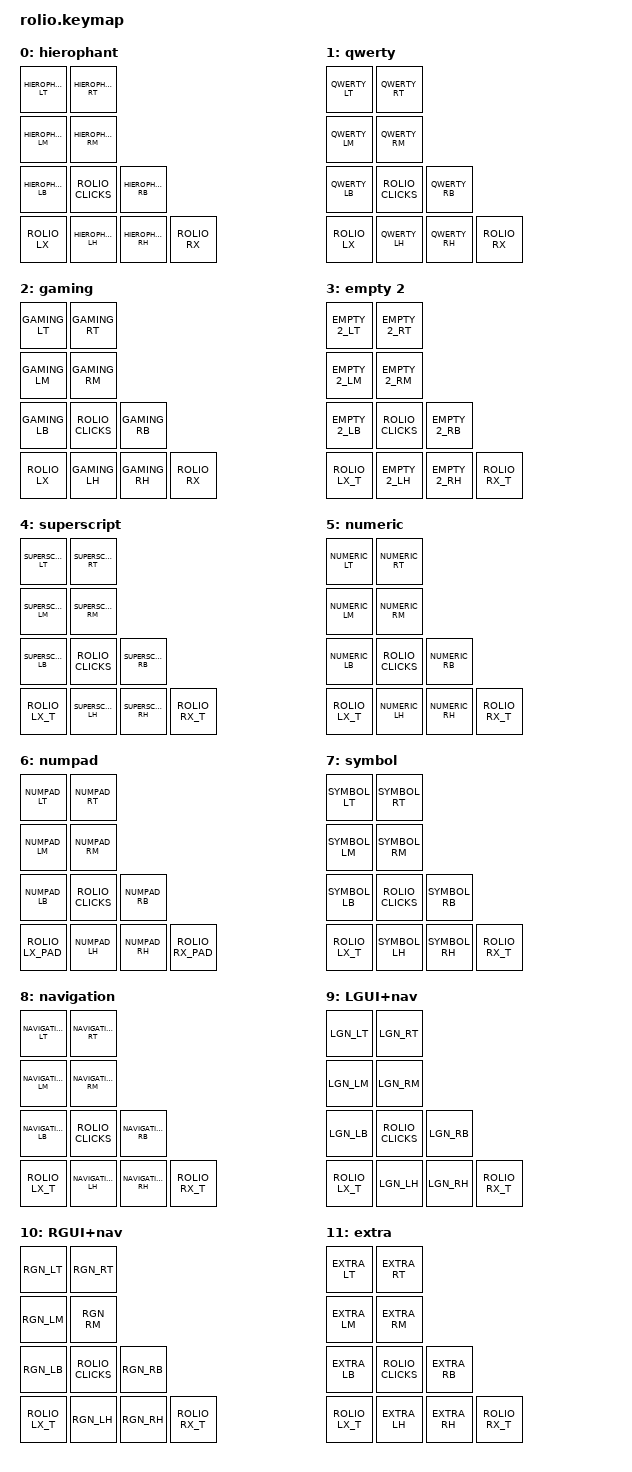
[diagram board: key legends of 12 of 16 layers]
// -*- mode: dts -*-
/*
 * Rolio ("Rolio Three") running the shared jjb layout.
 *
 * 48 matrix positions, 46 keycaps. Six columns per half exactly like the corne,
 * so X_LT / X_LM / X_LB drop straight in. What the shared layout has no slot
 * for is the bottom row's two outer "sometimes" keys per side (Sofle-style)
 * and the roller's push switch -- bound below rather than in jjb.keymap, since
 * no other board in this config has them.
 *
 * Hardware: Rolio Core V3 (config/boards/rolio/rolio3), vista508 display and
 * roller on the left half, Cirque trackpad and a second roller on the right.
 * Matrix wiring verified against the board, not taken from the vendor tree --
 * see config/boards/shields/rolio/rolio.dtsi.
 */

#define CONFIG_WIRELESS

#include "rolio48.h"
#include "jjb.keymap"

/* Bottom-row extras, left pair is (outer, inner), right pair is (inner, outer).
   The shared layout has no slot for these, so they are bound here.

   On the base layers the left pair splits apart the tap-dance that the outer
   left thumb (&sl_sym_or_numpad) otherwise packs onto one key: tap for sticky
   SYMBOL, double-tap for smart NUMPAD. Given dedicated keys, both are a single
   press. Swap the two if the inner position suits SYMBOL better in practice.

   The right pair stays inert -- mirroring these would collide with the right
   half's own thumb behaviours. */
#define ROLIO_LX &sl_long SYMBOL  &numpad_word NUMPAD
/* Mirrors the left pair. Note the order differs: the left pair reads
   outer-then-inner, the right inner-then-outer, so both put numpad on the
   fourth thumb key and sticky SYMBOL on the fifth, counting outward. */
#define ROLIO_RX &numpad_word NUMPAD  &sl_long SYMBOL

/* Non-base layers inherit rather than re-triggering a layer switch from within
   a layer, so the extras fall through there. */
#define ROLIO_LX_T &trans &trans
#define ROLIO_RX_T &trans &trans

/* NUMPAD is the exception. Falling through gave it sticky SYMBOL on the far
   keys, which stacks SYMBOL over NUMPAD so SYMBOL's &trans keys type digits,
   and numpad_word on the near ones. Given the only spare thumb-row keys on any
   board, spend them on what numeric entry lacks.

   Left pair reads outer-then-inner, so `(` sits left of `)` as written. Both
   are shifted digits (LS(N9), LS(N0)), which ignore-numbers treats as digits,
   so an expression stays in word mode.

   Right pair reads inner-then-outer: `=` on the nearer key, and on the far one
   the silent way out -- numpad_word pressed while word mode is armed turns it
   off without typing anything, which no key on the 3-thumb boards can do. */
#define ROLIO_LX_PAD &kp LPAR   &kp RPAR
#define ROLIO_RX_PAD &kp EQUAL  &numpad_word NUMPAD

/*
 * Soft off, Rolio only.
 *
 * CONFIG_ZMK_PM_SOFT_OFF and the wakeup apparatus in both overlays are this
 * board's; putting &soft_off in the shared layout would fail to build on a
 * keyboard that has neither. So SYSTEM's left thumbs are overridden here.
 *
 * It sits on the OUTER thumb, with the way back out on the inner one, because
 * the two should not be neighbours: SYSTEM is now only reachable deliberately,
 * but "power the keyboard off" and "leave this layer" being adjacent is asking
 * for it.
 */
#undef SYSTEM_LH
#define SYSTEM_LH &soft_off &emblem_home &to HIEROPHANT

/*
 * Swap the emblem and leave SYSTEM in one press.
 *
 * The layer half is deliberately HERE rather than inside the behaviour: which
 * layer is "home" is a property of this keymap, not of a display toggle, and
 * the neighbouring key already says HIEROPHANT. Keeping both in one place
 * means they cannot drift apart.
 *
 * SYSTEM is entered with &to, which LOCKS the layer, so only another &to gets
 * out of it -- an unlocking deactivate is ignored.
 */
ZMK_MACRO(emblem_home, bindings = <&emblem_toggle>, <&to HIEROPHANT>;)

/* Roller push switches, left and right. The eyelash_corne binds its equivalent
   inner key (LEC) to &kp C_MUTE; left inert here pending your preference. */
/*
 * Roller push switches. Mute on the left, matching the eyelash's inner key.
 * The right is deliberately still inert -- the trackpad already handles clicks,
 * so there is nothing obvious it should do, and these two are the only keys on
 * the board with no LED under them, which makes them poor homes for anything
 * whose state you would want to see.
 */
#define ROLIO_CLICKS &kp C_MUTE &trans

/* Both halves have a roller. Left: volume. Right: page up/down -- matching the
   sofle build. NOTE: the encoders are currently disabled in the shield because
   their GPIOs are still unidentified, so these bindings are inert for now. */
#define ROLIO_SENSORS <&inc_dec_kp C_VOL_UP C_VOL_DN &inc_dec_kp PG_UP PG_DN>

/ {
    keymap {
        compatible = "zmk,keymap";

        hierophant_layer {
            display-name = "hierophant";
            bindings = <
HIEROPHANT_LT HIEROPHANT_RT
HIEROPHANT_LM HIEROPHANT_RM
HIEROPHANT_LB ROLIO_CLICKS HIEROPHANT_RB
ROLIO_LX HIEROPHANT_LH  HIEROPHANT_RH ROLIO_RX
            >;
            sensor-bindings = ROLIO_SENSORS;
        };

        qwerty_layer {
            display-name = "qwerty";
            bindings = <
QWERTY_LT QWERTY_RT
QWERTY_LM QWERTY_RM
QWERTY_LB ROLIO_CLICKS QWERTY_RB
ROLIO_LX QWERTY_LH  QWERTY_RH ROLIO_RX
            >;
            sensor-bindings = ROLIO_SENSORS;
        };

        gaming_layer {
            display-name = "gaming";
            bindings = <
GAMING_LT GAMING_RT
GAMING_LM GAMING_RM
GAMING_LB ROLIO_CLICKS GAMING_RB
ROLIO_LX GAMING_LH  GAMING_RH ROLIO_RX
            >;
            sensor-bindings = ROLIO_SENSORS;
        };

        empty_2_layer {
            display-name = "empty 2";
            bindings = <
EMPTY_2_LT EMPTY_2_RT
EMPTY_2_LM EMPTY_2_RM
EMPTY_2_LB ROLIO_CLICKS EMPTY_2_RB
ROLIO_LX_T EMPTY_2_LH  EMPTY_2_RH ROLIO_RX_T
            >;
        };

        superscript_layer {
            display-name = "superscript";
            bindings = <
SUPERSCRIPT_LT SUPERSCRIPT_RT
SUPERSCRIPT_LM SUPERSCRIPT_RM
SUPERSCRIPT_LB ROLIO_CLICKS SUPERSCRIPT_RB
ROLIO_LX_T SUPERSCRIPT_LH  SUPERSCRIPT_RH ROLIO_RX_T
            >;
        };

        numeric_layer {
            display-name = "numeric";
            bindings = <
NUMERIC_LT NUMERIC_RT
NUMERIC_LM NUMERIC_RM
NUMERIC_LB ROLIO_CLICKS NUMERIC_RB
ROLIO_LX_T NUMERIC_LH  NUMERIC_RH ROLIO_RX_T
            >;
        };

        numpad_layer {
            display-name = "numpad";
            bindings = <
NUMPAD_LT NUMPAD_RT
NUMPAD_LM NUMPAD_RM
NUMPAD_LB ROLIO_CLICKS NUMPAD_RB
ROLIO_LX_PAD NUMPAD_LH  NUMPAD_RH ROLIO_RX_PAD
            >;
        };

        symbol_layer {
            display-name = "symbol";
            bindings = <
SYMBOL_LT SYMBOL_RT
SYMBOL_LM SYMBOL_RM
SYMBOL_LB ROLIO_CLICKS SYMBOL_RB
ROLIO_LX_T SYMBOL_LH  SYMBOL_RH ROLIO_RX_T
            >;
        };

        navigation_layer {
            display-name = "navigation";
            bindings = <
NAVIGATION_LT NAVIGATION_RT
NAVIGATION_LM NAVIGATION_RM
NAVIGATION_LB ROLIO_CLICKS NAVIGATION_RB
ROLIO_LX_T NAVIGATION_LH  NAVIGATION_RH ROLIO_RX_T
            >;
        };

        mod_l_nav_layer {
            display-name = "LGUI+nav";
            bindings = <
LGN_LT LGN_RT
LGN_LM LGN_RM
LGN_LB ROLIO_CLICKS LGN_RB
ROLIO_LX_T LGN_LH  LGN_RH ROLIO_RX_T
            >;
        };

        mod_r_nav_layer {
            display-name = "RGUI+nav";
            bindings = <
RGN_LT RGN_RT
RGN_LM RGN_RM
RGN_LB ROLIO_CLICKS RGN_RB
ROLIO_LX_T RGN_LH  RGN_RH ROLIO_RX_T
            >;
        };

        extra_layer {
            display-name = "extra";
            bindings = <
EXTRA_LT EXTRA_RT
EXTRA_LM EXTRA_RM
EXTRA_LB ROLIO_CLICKS EXTRA_RB
ROLIO_LX_T EXTRA_LH  EXTRA_RH ROLIO_RX_T
            >;
        };

        function_layer {
            display-name = "function";
            bindings = <
FUNCTION_LT FUNCTION_RT
FUNCTION_LM FUNCTION_RM
FUNCTION_LB ROLIO_CLICKS FUNCTION_RB
ROLIO_LX_T FUNCTION_LH  FUNCTION_RH ROLIO_RX_T
            >;
        };

        lighting_layer {
            display-name = "lighting";
            bindings = <
LIGHTING_LT LIGHTING_RT
LIGHTING_LM LIGHTING_RM
LIGHTING_LB ROLIO_CLICKS LIGHTING_RB
ROLIO_LX_T LIGHTING_LH  LIGHTING_RH ROLIO_RX_T
            >;
        };

        bluetooth_layer {
            display-name = "bluetooth";
            bindings = <
BLUETOOTH_LT BLUETOOTH_RT
BLUETOOTH_LM BLUETOOTH_RM
BLUETOOTH_LB ROLIO_CLICKS BLUETOOTH_RB
ROLIO_LX_T BLUETOOTH_LH  BLUETOOTH_RH ROLIO_RX_T
            >;
        };

        system_layer {
            display-name = "system";
            bindings = <
SYSTEM_LT SYSTEM_RT
SYSTEM_LM SYSTEM_RM
SYSTEM_LB ROLIO_CLICKS SYSTEM_RB
ROLIO_LX_T SYSTEM_LH  SYSTEM_RH ROLIO_RX_T
            >;
        };

    }; /* keymap */
}; // root node
